VERSION ""

NS_ :

BS_:

BU_: MAG_BOARD

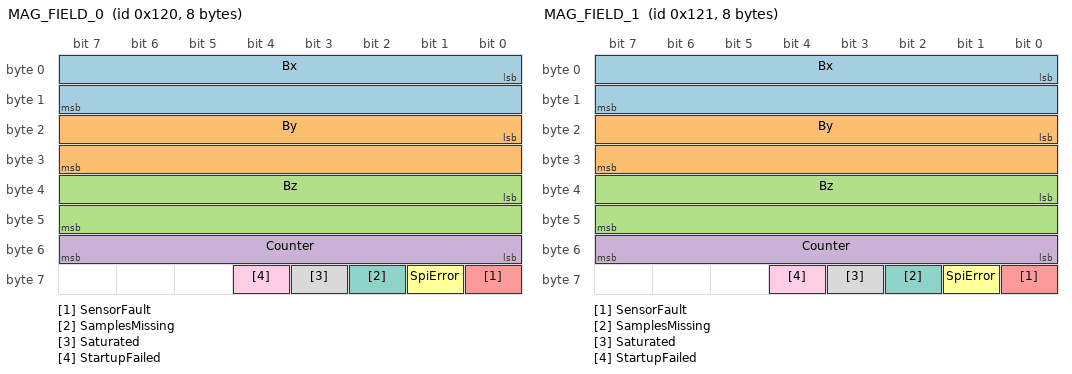
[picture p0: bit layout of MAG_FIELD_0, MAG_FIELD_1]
BO_ 288 MAG_FIELD_0: 8 MAG_BOARD
 SG_ Bx : 0|16@1- (0.01,0) [-327.68|327.67] "mT" Vector__XXX
 SG_ By : 16|16@1- (0.01,0) [-327.68|327.67] "mT" Vector__XXX
 SG_ Bz : 32|16@1- (0.01,0) [-327.68|327.67] "mT" Vector__XXX
 SG_ Counter : 48|8@1+ (1,0) [0|255] "" Vector__XXX
 SG_ SensorFault : 56|1@1+ (1,0) [0|1] "" Vector__XXX
 SG_ SpiError : 57|1@1+ (1,0) [0|1] "" Vector__XXX
 SG_ SamplesMissing : 58|1@1+ (1,0) [0|1] "" Vector__XXX
 SG_ Saturated : 59|1@1+ (1,0) [0|1] "" Vector__XXX
 SG_ StartupFailed : 60|1@1+ (1,0) [0|1] "" Vector__XXX

BO_ 289 MAG_FIELD_1: 8 MAG_BOARD
 SG_ Bx : 0|16@1- (0.01,0) [-327.68|327.67] "mT" Vector__XXX
 SG_ By : 16|16@1- (0.01,0) [-327.68|327.67] "mT" Vector__XXX
 SG_ Bz : 32|16@1- (0.01,0) [-327.68|327.67] "mT" Vector__XXX
 SG_ Counter : 48|8@1+ (1,0) [0|255] "" Vector__XXX
 SG_ SensorFault : 56|1@1+ (1,0) [0|1] "" Vector__XXX
 SG_ SpiError : 57|1@1+ (1,0) [0|1] "" Vector__XXX
 SG_ SamplesMissing : 58|1@1+ (1,0) [0|1] "" Vector__XXX
 SG_ Saturated : 59|1@1+ (1,0) [0|1] "" Vector__XXX
 SG_ StartupFailed : 60|1@1+ (1,0) [0|1] "" Vector__XXX

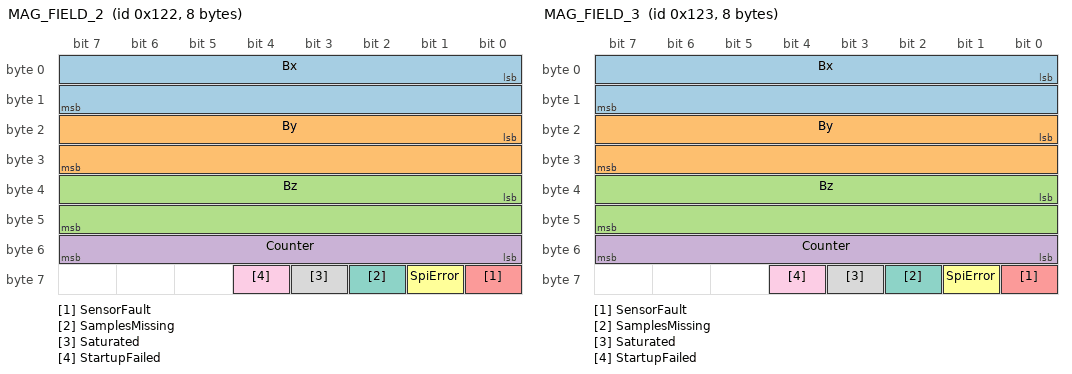
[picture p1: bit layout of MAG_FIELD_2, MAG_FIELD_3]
BO_ 290 MAG_FIELD_2: 8 MAG_BOARD
 SG_ Bx : 0|16@1- (0.01,0) [-327.68|327.67] "mT" Vector__XXX
 SG_ By : 16|16@1- (0.01,0) [-327.68|327.67] "mT" Vector__XXX
 SG_ Bz : 32|16@1- (0.01,0) [-327.68|327.67] "mT" Vector__XXX
 SG_ Counter : 48|8@1+ (1,0) [0|255] "" Vector__XXX
 SG_ SensorFault : 56|1@1+ (1,0) [0|1] "" Vector__XXX
 SG_ SpiError : 57|1@1+ (1,0) [0|1] "" Vector__XXX
 SG_ SamplesMissing : 58|1@1+ (1,0) [0|1] "" Vector__XXX
 SG_ Saturated : 59|1@1+ (1,0) [0|1] "" Vector__XXX
 SG_ StartupFailed : 60|1@1+ (1,0) [0|1] "" Vector__XXX

BO_ 291 MAG_FIELD_3: 8 MAG_BOARD
 SG_ Bx : 0|16@1- (0.01,0) [-327.68|327.67] "mT" Vector__XXX
 SG_ By : 16|16@1- (0.01,0) [-327.68|327.67] "mT" Vector__XXX
 SG_ Bz : 32|16@1- (0.01,0) [-327.68|327.67] "mT" Vector__XXX
 SG_ Counter : 48|8@1+ (1,0) [0|255] "" Vector__XXX
 SG_ SensorFault : 56|1@1+ (1,0) [0|1] "" Vector__XXX
 SG_ SpiError : 57|1@1+ (1,0) [0|1] "" Vector__XXX
 SG_ SamplesMissing : 58|1@1+ (1,0) [0|1] "" Vector__XXX
 SG_ Saturated : 59|1@1+ (1,0) [0|1] "" Vector__XXX
 SG_ StartupFailed : 60|1@1+ (1,0) [0|1] "" Vector__XXX

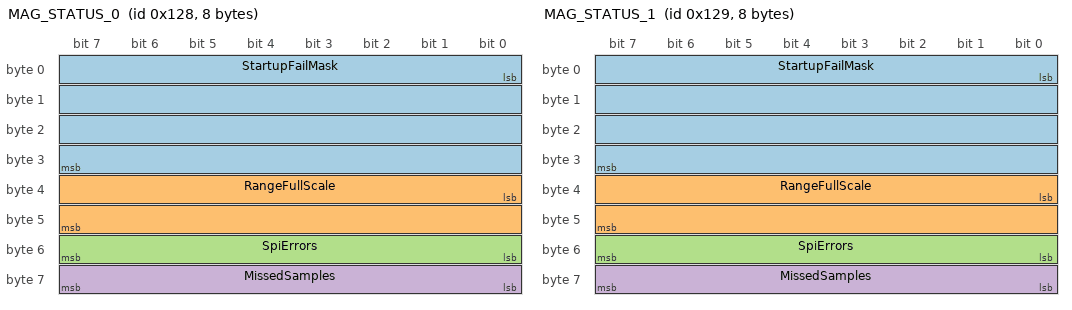
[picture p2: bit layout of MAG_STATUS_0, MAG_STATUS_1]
BO_ 296 MAG_STATUS_0: 8 MAG_BOARD
 SG_ StartupFailMask : 0|32@1+ (1,0) [0|4294967295] "" Vector__XXX
 SG_ RangeFullScale : 32|16@1+ (1,0) [0|65535] "mT" Vector__XXX
 SG_ SpiErrors : 48|8@1+ (1,0) [0|255] "" Vector__XXX
 SG_ MissedSamples : 56|8@1+ (1,0) [0|255] "" Vector__XXX

BO_ 297 MAG_STATUS_1: 8 MAG_BOARD
 SG_ StartupFailMask : 0|32@1+ (1,0) [0|4294967295] "" Vector__XXX
 SG_ RangeFullScale : 32|16@1+ (1,0) [0|65535] "mT" Vector__XXX
 SG_ SpiErrors : 48|8@1+ (1,0) [0|255] "" Vector__XXX
 SG_ MissedSamples : 56|8@1+ (1,0) [0|255] "" Vector__XXX

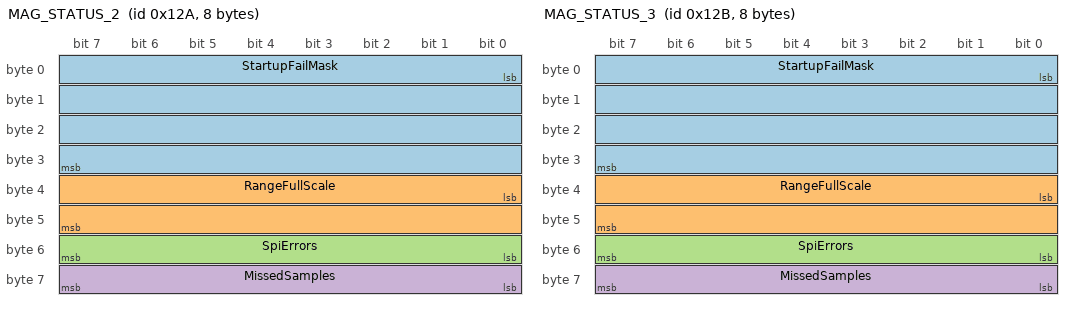
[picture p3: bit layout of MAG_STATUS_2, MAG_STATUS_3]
BO_ 298 MAG_STATUS_2: 8 MAG_BOARD
 SG_ StartupFailMask : 0|32@1+ (1,0) [0|4294967295] "" Vector__XXX
 SG_ RangeFullScale : 32|16@1+ (1,0) [0|65535] "mT" Vector__XXX
 SG_ SpiErrors : 48|8@1+ (1,0) [0|255] "" Vector__XXX
 SG_ MissedSamples : 56|8@1+ (1,0) [0|255] "" Vector__XXX

BO_ 299 MAG_STATUS_3: 8 MAG_BOARD
 SG_ StartupFailMask : 0|32@1+ (1,0) [0|4294967295] "" Vector__XXX
 SG_ RangeFullScale : 32|16@1+ (1,0) [0|65535] "mT" Vector__XXX
 SG_ SpiErrors : 48|8@1+ (1,0) [0|255] "" Vector__XXX
 SG_ MissedSamples : 56|8@1+ (1,0) [0|255] "" Vector__XXX

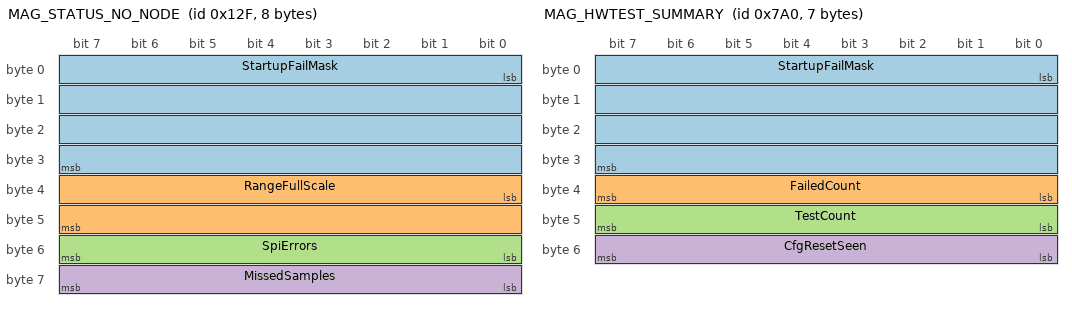
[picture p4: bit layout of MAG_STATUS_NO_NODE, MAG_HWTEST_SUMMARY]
BO_ 303 MAG_STATUS_NO_NODE: 8 MAG_BOARD
 SG_ StartupFailMask : 0|32@1+ (1,0) [0|4294967295] "" Vector__XXX
 SG_ RangeFullScale : 32|16@1+ (1,0) [0|65535] "mT" Vector__XXX
 SG_ SpiErrors : 48|8@1+ (1,0) [0|255] "" Vector__XXX
 SG_ MissedSamples : 56|8@1+ (1,0) [0|255] "" Vector__XXX

BO_ 1952 MAG_HWTEST_SUMMARY: 7 MAG_BOARD
 SG_ StartupFailMask : 0|32@1+ (1,0) [0|4294967295] "" Vector__XXX
 SG_ FailedCount : 32|8@1+ (1,0) [0|255] "" Vector__XXX
 SG_ TestCount : 40|8@1+ (1,0) [0|255] "" Vector__XXX
 SG_ CfgResetSeen : 48|8@1+ (1,0) [0|1] "" Vector__XXX

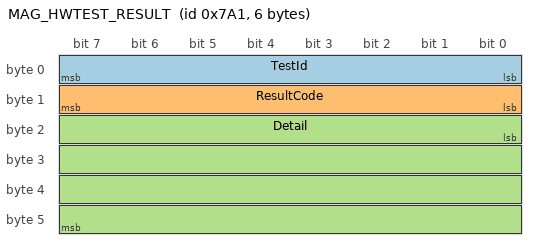
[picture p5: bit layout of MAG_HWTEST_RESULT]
BO_ 1953 MAG_HWTEST_RESULT: 6 MAG_BOARD
 SG_ TestId : 0|8@1+ (1,0) [0|255] "" Vector__XXX
 SG_ ResultCode : 8|8@1+ (1,0) [0|255] "" Vector__XXX
 SG_ Detail : 16|32@1+ (1,0) [0|4294967295] "" Vector__XXX

BO_ 1955 MAG_HWTEST_BUS_TX: 2 MAG_BOARD
 SG_ Pattern : 0|16@1+ (1,0) [0|65535] "" Vector__XXX

CM_ BU_ MAG_BOARD "STM32F072 + TMAG5170A2 magnetometer board (firmware/stm32/prod/mag_board)";
CM_ BO_ 288 "Node 0 (option byte Data0 = 0). 3-axis field, average of 10 samples taken at 1 kHz. 100 Hz.";
CM_ BO_ 289 "Node 1 (option byte Data0 = 1). Same layout as MAG_FIELD_0.";
CM_ BO_ 290 "Node 2 (option byte Data0 = 2). Same layout as MAG_FIELD_0.";
CM_ BO_ 291 "Node 3 (option byte Data0 = 3). Same layout as MAG_FIELD_0.";
CM_ SG_ 288 Counter "Increments by 1 per frame and wraps; a gap means dropped frames.";
CM_ SG_ 288 SensorFault "Sensor ERROR_STAT seen, sensor reset, or sensor not configured.";
CM_ SG_ 288 SpiError "SPI transfer or CRC error during this window.";
CM_ SG_ 288 SamplesMissing "Fewer than 10 valid samples averaged into this frame.";
CM_ SG_ 288 Saturated "An axis read full scale in at least one sample.";
CM_ SG_ 288 StartupFailed "MCU startup configuration checks failed; see MAG_STATUS_0.StartupFailMask.";
CM_ BO_ 296 "Node 0 board health. 1 Hz.";
CM_ BO_ 297 "Node 1 board health. Same layout as MAG_STATUS_0.";
CM_ BO_ 298 "Node 2 board health. Same layout as MAG_STATUS_0.";
CM_ BO_ 299 "Node 3 board health. Same layout as MAG_STATUS_0.";
CM_ BO_ 303 "Sent instead of MAG_FIELD/MAG_STATUS by a board whose option byte Data0 is not 0-3 (StartupFailMask bit 15 set). 1 Hz.";
CM_ SG_ 296 StartupFailMask "startup_fail_t bits, see firmware/stm32/prod/mag_board/include/startup_checks.h.";
CM_ SG_ 296 SpiErrors "SPI errors in the last second (saturates at 255).";
CM_ SG_ 296 MissedSamples "1 kHz sample slots without a valid sample in the last second (saturates at 255).";
CM_ BO_ 1952 "CAN test suite summary, only sent by MAG_BOARD_TEST_SUITE=CAN builds. 1 Hz.";
CM_ BO_ 1953 "CAN test suite result, one frame per test that ran, only sent by MAG_BOARD_TEST_SUITE=CAN builds. Codes: firmware/stm32/prod/mag_board/include/hw_results.h.";
CM_ BO_ 1955 "Sent once at boot by the CAN test suite to check another node ACKs. Pattern = 0xFECA (bytes CA FE).";

VAL_ 1953 TestId 0 "CONFIG" 1 "IDLE_LEVELS" 2 "SPI_LINK" 3 "SENSOR_STATUS" 4 "SPI_WRITE_READ" 5 "ALERT_SENSOR" 6 "ALERT_JUMPER" 7 "CAN_LOOPBACK" 8 "SENSOR_READ" 9 "CAN_BUS_TX" ;
VAL_ 1953 ResultCode 0 "NOT_RUN" 1 "PASS" 2 "SKIPPED" 3 "NOT_NEEDED" 10 "FAIL_CONFIG" 20 "FAIL_CS_N_LOW" 21 "FAIL_CAN_STM_HIGH" 22 "FAIL_ALERT_STUCK_LOW" 30 "FAIL_SPI_HAL" 31 "FAIL_SPI_ALL_FF" 32 "FAIL_SPI_ALL_00" 33 "FAIL_SPI_CRC" 34 "FAIL_SPI_SENSOR_SAW_BAD_CRC" 35 "FAIL_SPI_UNEXPECTED_VALUE" 40 "FAIL_READBACK_MISMATCH" 41 "FAIL_SENSOR_FAULT_FLAGS" 42 "FAIL_SENSOR_SPI_FLAGS" 43 "FAIL_SENSOR_CONFIG" 44 "FAIL_SENSOR_STALE" 45 "FAIL_SENSOR_SATURATED" 50 "FAIL_ALERT_NOT_ASSERTED" 51 "FAIL_ALERT_NO_IRQ" 52 "FAIL_ALERT_NOT_RELEASED" 53 "FAIL_ALERT_JUMPER_TIMEOUT" 54 "FAIL_ALERT_ASSERTED_EARLY" 60 "FAIL_CAN_INIT" 61 "FAIL_CAN_TX" 62 "FAIL_CAN_RX_TIMEOUT" 63 "FAIL_CAN_RX_MISMATCH" 64 "FAIL_CAN_NO_ACK" 65 "FAIL_CAN_BUS_ERROR" 66 "FAIL_CAN_BUS_OFF" ;
